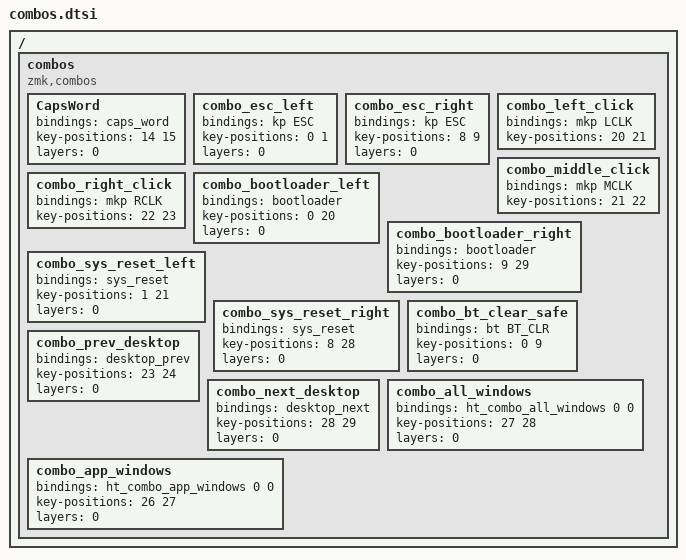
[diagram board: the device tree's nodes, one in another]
/* --- KEY ID LAYOUT (3x5 Charybdis Nano, 35 keys) --- */
// ╭──────┬──────┬──────┬──────┬──────╮  ╭──────┬──────┬──────┬──────┬──────╮
//    00     01     02     03     04        05     06     07     08     09
// ├──────┼──────┼──────┼──────┼──────┤  ├──────┼──────┼──────┼──────┼──────┤
//    10     11     12     13     14        15     16     17     18     19
// ├──────┼──────┼──────┼──────┼──────┤  ├──────┼──────┼──────┼──────┼──────┤
//    20     21     22     23     24        25     26     27     28     29
// ╰──────┴──────┴──────┼──────┼──────┤  ├──────┼──────┼──────┴──────┴──────╯
//                         30     31     32     33     34
//                      ╰──────┴──────┴──────╯  ╰──────┴──────╯
//
// bootloader and sys_reset are SAME-HAND on purpose: top + bottom of one
// column, a chord that never comes up while typing, and neither needs the
// other half. That matters because the split link is exactly what you may be
// trying to recover from.
//
//   outer column (00/20, 09/29)   -> bootloader
//   second column (01/21, 08/28)  -> sys_reset

/ {
    combos {
        compatible = "zmk,combos";

        CapsWord {
            bindings = <&caps_word>;
            key-positions = <14 15>;   // G + H
            layers = <0>;
        };

        combo_esc_left {
            bindings = <&kp ESC>;
            key-positions = <0 1>;     // Q + W
            layers = <0>;
        };

        combo_esc_right {
            bindings = <&kp ESC>;
            key-positions = <8 9>;     // O + P
            layers = <0>;
        };

        /* Clicks also live on J/K/L in the SCROLL layer; these keep them
           reachable from BASE without entering a layer. */
        combo_left_click {
            bindings = <&mkp LCLK>;
            key-positions = <20 21>;   // Z + X
        };

        combo_middle_click {
            bindings = <&mkp MCLK>;
            key-positions = <21 22>;   // X + C
        };

        combo_right_click {
            bindings = <&mkp RCLK>;
            key-positions = <22 23>;   // C + V
        };

        combo_bootloader_left {
            bindings = <&bootloader>;
            key-positions = <0 20>;    // Q + Z
            layers = <0>;
        };

        combo_bootloader_right {
            bindings = <&bootloader>;
            key-positions = <9 29>;    // P + ?/!
            layers = <0>;
        };

        /* NEW: this repo had no sys_reset binding at all. A soft MCU reset is
           the thing you want when the split link drops, instead of reaching for
           the physical button. */
        combo_sys_reset_left {
            bindings = <&sys_reset>;
            key-positions = <1 21>;    // W + X
            layers = <0>;
        };

        combo_sys_reset_right {
            bindings = <&sys_reset>;
            key-positions = <8 28>;    // O + .:
            layers = <0>;
        };

        /* Clears the active BLE profile. Spans both halves so it cannot fire by
           accident - but that also means it is useless while the split is down;
           use settings_reset firmware in that case. */
        combo_bt_clear_safe {
            bindings = <&bt BT_CLR>;
            key-positions = <0 9>;     // Q + P (top corners)
            layers = <0>;
        };

        combo_prev_desktop {
            bindings = <&desktop_prev>;
            key-positions = <23 24>;   // V + B
            layers = <0>;
        };

        combo_next_desktop {
            bindings = <&desktop_next>;
            key-positions = <28 29>;
            layers = <0>;
        };

        combo_all_windows {
            bindings = <&ht_combo_all_windows 0 0>;
            key-positions = <27 28>;
            layers = <0>;
        };

        combo_app_windows {
            // KDE Present Windows (current app/window class).
            bindings = <&ht_combo_app_windows 0 0>;
            key-positions = <26 27>;
            layers = <0>;
        };
    };
};
